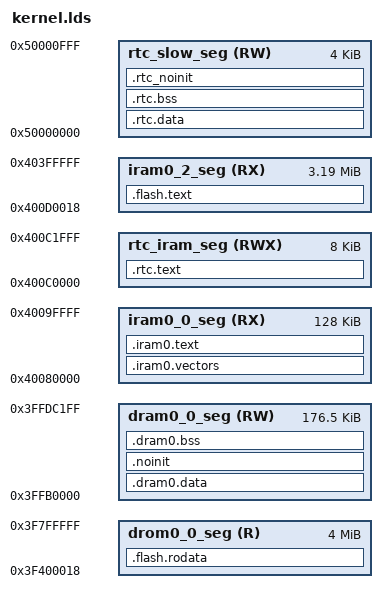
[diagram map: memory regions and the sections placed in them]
/* ESP32 Linker Script Memory Layout

   This file describes the memory layout (memory blocks) as virtual
   memory addresses.

   esp32.common.ld contains output sections to link compiler output
   into these memory blocks.

   ***

   This linker script is passed through the C preprocessor to include
   configuration options.

   Please use preprocessor features sparingly! Restrict
   to simple macros with numeric values, and/or #if/#endif blocks.
*/
/*
 *
 * Automatically generated file; DO NOT EDIT.
 * Espressif IoT Development Framework Configuration
 *
 */
/* If BT is not built at all */
MEMORY
{
  /* All these values assume the flash cache is on, and have the blocks this uses subtracted from the length
  of the various regions. The 'data access port' dram/drom regions map to the same iram/irom regions but
  are connected to the data port of the CPU and eg allow bytewise access. */
  /* IRAM for PRO cpu. Not sure if happy with this, this is MMU area... */
  iram0_0_seg (RX) : org = 0x40080000, len = 0x20000
  /* Even though the segment name is iram, it is actually mapped to flash
  */
  iram0_2_seg (RX) : org = 0x400D0018, len = 0x330000-0x18
  /*
    (0x18 offset above is a convenience for the app binary image generation. Flash cache has 64KB pages. The .bin file
    which is flashed to the chip has a 0x18 byte file header. Setting this offset makes it simple to meet the flash
    cache MMU's constraint that (paddr % 64KB == vaddr % 64KB).)
  */
  /* Shared data RAM, excluding memory reserved for ROM bss/data/stack.

     Enabling Bluetooth & Trace Memory features in menuconfig will decrease
     the amount of RAM available.

     Note: Length of this section *should* be 0x50000, and this extra DRAM is available
     in heap at runtime. However due to static ROM memory usage at this 176KB mark, the
     additional static memory temporarily cannot be used.
  */
  dram0_0_seg (RW) : org = 0x3FFB0000 + 0x0,
                                     len = 0x2c200 - 0x0
  /* Flash mapped constant data */
  drom0_0_seg (R) : org = 0x3F400018, len = 0x400000-0x18
  /* (See iram0_2_seg for meaning of 0x18 offset in the above.) */
  /* RTC fast memory (executable). Persists over deep sleep.
   */
  rtc_iram_seg(RWX) : org = 0x400C0000, len = 0x2000
  /* RTC slow memory (data accessible). Persists over deep sleep.

     Start of RTC slow memory is reserved for ULP co-processor code + data, if enabled.
  */
  rtc_slow_seg(RW) : org = 0x50000000 + 0,
                                     len = 0x1000 - 0
}
/* Heap ends at top of dram0_0_seg */
_heap_end = 0x40000000 - 0x0;

/*  Default entry point:  */
ENTRY(BSPKernelEntry);

SECTIONS
{
  /* RTC fast memory holds RTC wake stub code,
     including from any source file named rtc_wake_stub*.c
  */
  .rtc.text :
  {
    . = ALIGN(4);
    *(.rtc.literal .rtc.text)
    *rtc_wake_stub*.o(.literal .text .literal.* .text.*)
  } > rtc_iram_seg

  /* RTC slow memory holds RTC wake stub
     data/rodata, including from any source file
     named rtc_wake_stub*.c
  */
  .rtc.data :
  {
    _rtc_data_start = ABSOLUTE(.);
    *(.rtc.data)
    *(.rtc.rodata)
    *rtc_wake_stub*.o(.data .rodata .data.* .rodata.* .bss .bss.*)
    _rtc_data_end = ABSOLUTE(.);
  } > rtc_slow_seg

  /* RTC bss, from any source file named rtc_wake_stub*.c */
  .rtc.bss (NOLOAD) :
  {
    _rtc_bss_start = ABSOLUTE(.);
    *rtc_wake_stub*.o(.bss .bss.*)
    *rtc_wake_stub*.o(COMMON)
    *(.rtc.bss)
    _rtc_bss_end = ABSOLUTE(.);
  } > rtc_slow_seg

  /* This section holds data that should not be initialized at power up 
     and will be retained during deep sleep. The section located in 
     RTC SLOW Memory area. User data marked with RTC_NOINIT_ATTR will be placed
     into this section. See the file "esp_attr.h" for more information.
  */
  .rtc_noinit (NOLOAD):
  {
    . = ALIGN(4);
    _rtc_noinit_start = ABSOLUTE(.);
    *(.rtc_noinit .rtc_noinit.*)
    . = ALIGN(4) ;
    _rtc_noinit_end = ABSOLUTE(.);
  } > rtc_slow_seg

  /* Send .iram0 code to iram */
  .iram0.vectors :
  {
    _iram_start = ABSOLUTE(.);
    /* Vectors go to IRAM */
    _init_start = ABSOLUTE(.);
    /* Vectors according to builds/RF-2015.2-win32/esp108_v1_2_s5_512int_2/config.html */
    . = 0x0;
    KEEP(*(.WindowVectors.text));
    . = 0x180;
    KEEP(*(.Level2InterruptVector.text));
    . = 0x1c0;
    KEEP(*(.Level3InterruptVector.text));
    . = 0x200;
    KEEP(*(.Level4InterruptVector.text));
    . = 0x240;
    KEEP(*(.Level5InterruptVector.text));
    . = 0x280;
    KEEP(*(.DebugExceptionVector.text));
    . = 0x2c0;
    KEEP(*(.NMIExceptionVector.text));
    . = 0x300;
    KEEP(*(.KernelExceptionVector.text));
    . = 0x340;
    KEEP(*(.UserExceptionVector.text));
    . = 0x3C0;
    KEEP(*(.DoubleExceptionVector.text));
    . = 0x400;
    *(.*Vector.literal)

    *(.UserEnter.literal);
    *(.UserEnter.text);
    . = ALIGN (16);
    *(.entry.text)
    *(.init.literal)
    *(.init)
    _init_end = ABSOLUTE(.);
} > iram0_0_seg

  .iram0.text :
  {
    /* Code marked as runnning out of IRAM */
    _iram_text_start = ABSOLUTE(.);
    *(.iram1 .iram1.*)
    *libfreertos.a:(.literal .text .literal.* .text.*)
    *libheap.a:multi_heap.o(.literal .text .literal.* .text.*)
    *libheap.a:multi_heap_poisoning.o(.literal .text .literal.* .text.*)
    *libesp32.a:panic.o(.literal .text .literal.* .text.*)
    *libesp32.a:core_dump.o(.literal .text .literal.* .text.*)
    *libapp_trace.a:(.literal .text .literal.* .text.*)
    *libxtensa-debug-module.a:eri.o(.literal .text .literal.* .text.*)
    *librtc.a:(.literal .text .literal.* .text.*)
    *libsoc.a:rtc_*.o(.literal .text .literal.* .text.*)
    *libsoc.a:cpu_util.o(.literal .text .literal.* .text.*)
    *libhal.a:(.literal .text .literal.* .text.*)
    *libgcc.a:lib2funcs.o(.literal .text .literal.* .text.*)
    *libspi_flash.a:spi_flash_rom_patch.o(.literal .text .literal.* .text.*)
    *libgcov.a:(.literal .text .literal.* .text.*)
    _iram_text_end = ABSOLUTE(.);
    _iram_end = ABSOLUTE(.);
  } > iram0_0_seg

  .dram0.data :
  {
    _data_start = ABSOLUTE(.);
    _bt_data_start = ABSOLUTE(.);
    *libbt.a:(.data .data.*)
    . = ALIGN (4);
    _bt_data_end = ABSOLUTE(.);
    _btdm_data_start = ABSOLUTE(.);
    *libbtdm_app.a:(.data .data.*)
    . = ALIGN (4);
    _btdm_data_end = ABSOLUTE(.);
    *(.data)
    *(.data.*)
    *(.gnu.linkonce.d.*)
    *(.data1)
    *(.sdata)
    *(.sdata.*)
    *(.gnu.linkonce.s.*)
    *(.sdata2)
    *(.sdata2.*)
    *(.gnu.linkonce.s2.*)
    *(.jcr)
    *(.dram1 .dram1.*)
    *libesp32.a:panic.o(.rodata .rodata.*)
    *libphy.a:(.rodata .rodata.*)
    *libsoc.a:rtc_clk.o(.rodata .rodata.*)
    *libapp_trace.a:(.rodata .rodata.*)
    *libgcov.a:(.rodata .rodata.*)
    *libheap.a:multi_heap.o(.rodata .rodata.*)
    *libheap.a:multi_heap_poisoning.o(.rodata .rodata.*)
    _data_end = ABSOLUTE(.);
    . = ALIGN(4);
  } > dram0_0_seg

  /*This section holds data that should not be initialized at power up.
    The section located in Internal SRAM memory region. The macro _NOINIT
    can be used as attribute to place data into this section.
    See the esp_attr.h file for more information.
  */
  .noinit (NOLOAD):
  {
    . = ALIGN(4);
    _noinit_start = ABSOLUTE(.);
    *(.noinit .noinit.*) 
    . = ALIGN(4) ;
    _noinit_end = ABSOLUTE(.);
  } > dram0_0_seg

  /* Shared RAM */
  .dram0.bss (NOLOAD) :
  {
    . = ALIGN (8);
    _bss_start = ABSOLUTE(.);
    _bt_bss_start = ABSOLUTE(.);
    *libbt.a:(.bss .bss.* COMMON)
    . = ALIGN (4);
    _bt_bss_end = ABSOLUTE(.);
    _btdm_bss_start = ABSOLUTE(.);
    *libbtdm_app.a:(.bss .bss.* COMMON)
    . = ALIGN (4);
    _btdm_bss_end = ABSOLUTE(.);
    *(.dynsbss)
    *(.sbss)
    *(.sbss.*)
    *(.gnu.linkonce.sb.*)
    *(.scommon)
    *(.sbss2)
    *(.sbss2.*)
    *(.gnu.linkonce.sb2.*)
    *(.dynbss)
    *(.bss)
    *(.bss.*)
    *(.share.mem)
    *(.gnu.linkonce.b.*)
    *(COMMON)
    . = ALIGN (8);
    _bss_end = ABSOLUTE(.);
    /* The heap starts right after end of this section */
    _heap_start = ABSOLUTE(.);
  } > dram0_0_seg

  .flash.rodata :
  {
    _rodata_start = ABSOLUTE(.);
    *(.rodata)
    *(.rodata.*)
    *(.irom1.text) /* catch stray ICACHE_RODATA_ATTR */
    *(.gnu.linkonce.r.*)
    *(.rodata1)
    __XT_EXCEPTION_TABLE_ = ABSOLUTE(.);
    *(.xt_except_table)
    *(.gcc_except_table .gcc_except_table.*)
    *(.gnu.linkonce.e.*)
    *(.gnu.version_r)
    . = (. + 3) & ~ 3;
    __eh_frame = ABSOLUTE(.);
    KEEP(*(.eh_frame))
    . = (. + 7) & ~ 3;
    /*  C++ constructor and destructor tables, properly ordered:  */
    __init_array_start = ABSOLUTE(.);
    KEEP (*crtbegin.o(.ctors))
    KEEP (*(EXCLUDE_FILE (*crtend.o) .ctors))
    KEEP (*(SORT(.ctors.*)))
    KEEP (*(.ctors))
    __init_array_end = ABSOLUTE(.);
    KEEP (*crtbegin.o(.dtors))
    KEEP (*(EXCLUDE_FILE (*crtend.o) .dtors))
    KEEP (*(SORT(.dtors.*)))
    KEEP (*(.dtors))
    /*  C++ exception handlers table:  */
    __XT_EXCEPTION_DESCS_ = ABSOLUTE(.);
    *(.xt_except_desc)
    *(.gnu.linkonce.h.*)
    __XT_EXCEPTION_DESCS_END__ = ABSOLUTE(.);
    *(.xt_except_desc_end)
    *(.dynamic)
    *(.gnu.version_d)
    /* Addresses of memory regions reserved via
       SOC_RESERVE_MEMORY_REGION() */
    soc_reserved_memory_region_start = ABSOLUTE(.);
    KEEP (*(.reserved_memory_address))
    soc_reserved_memory_region_end = ABSOLUTE(.);
    _rodata_end = ABSOLUTE(.);
    /* Literals are also RO data. */
    _lit4_start = ABSOLUTE(.);
    *(*.lit4)
    *(.lit4.*)
    *(.gnu.linkonce.lit4.*)
    _lit4_end = ABSOLUTE(.);
    . = ALIGN(4);
    _thread_local_start = ABSOLUTE(.);
    *(.tdata)
    *(.tdata.*)
    *(.tbss)
    *(.tbss.*)
    _thread_local_end = ABSOLUTE(.);
    . = ALIGN(4);
  } >drom0_0_seg

  .flash.text :
  {
    _stext = .;
    _text_start = ABSOLUTE(.);
    *(.literal .text .literal.* .text.* .stub .gnu.warning .gnu.linkonce.literal.* .gnu.linkonce.t.*.literal .gnu.linkonce.t.*)
    *(.irom0.text) /* catch stray ICACHE_RODATA_ATTR */
    *(.fini.literal)
    *(.fini)
    *(.gnu.version)
    _text_end = ABSOLUTE(.);
    _etext = .;

    /* Similar to _iram_start, this symbol goes here so it is
       resolved by addr2line in preference to the first symbol in
       the flash.text segment.
    */
    _flash_cache_start = ABSOLUTE(0);
  } >iram0_2_seg
}
